VERSION ""

NS_ :

BS_:

BU_: TTC_580 TTC32

BO_ 2557673601 Axiomatic: 8 Vector__XXX
 SG_ Axiomatic_PWM : 0|32@1+ (1,0) [0|0] "" Vector__XXX

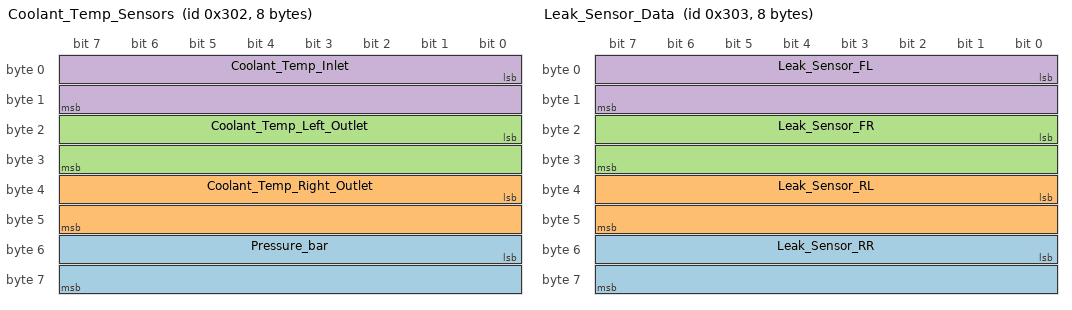
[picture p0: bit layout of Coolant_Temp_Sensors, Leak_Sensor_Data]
BO_ 770 Coolant_Temp_Sensors: 8 Vector__XXX
 SG_ Pressure_bar : 48|16@1+ (1,0) [0|65535] "bar" Vector__XXX
 SG_ Coolant_Temp_Right_Outlet : 32|16@1- (1,30.4) [-32737.6|32797.4] "C" Vector__XXX
 SG_ Coolant_Temp_Left_Outlet : 16|16@1- (1,30.4) [-32737.6|32797.4] "C" Vector__XXX
 SG_ Coolant_Temp_Inlet : 0|16@1- (1,30.4) [-32737.6|32797.4] "C" Vector__XXX

BO_ 771 Leak_Sensor_Data: 8 TTC32
 SG_ Leak_Sensor_RR : 48|16@1- (1,0) [-128|127] ""  TTC_580
 SG_ Leak_Sensor_RL : 32|16@1- (1,0) [-128|127] ""  TTC_580
 SG_ Leak_Sensor_FR : 16|16@1- (1,0) [-128|127] ""  TTC_580
 SG_ Leak_Sensor_FL : 0|16@1- (1,0) [-128|127] ""  TTC_580

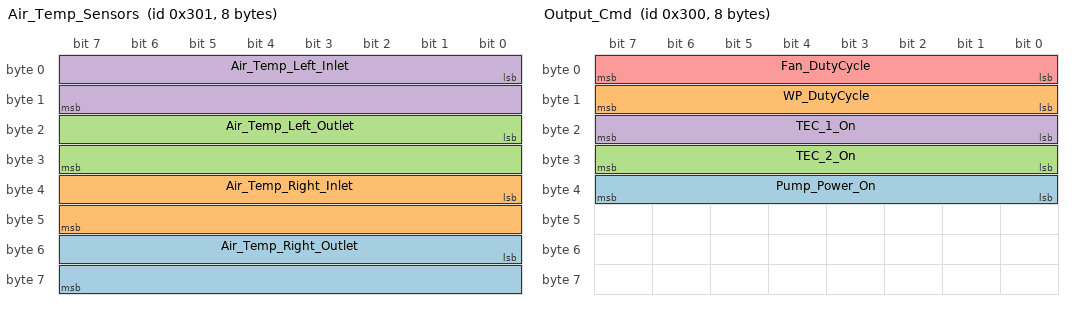
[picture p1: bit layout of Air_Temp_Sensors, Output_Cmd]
BO_ 769 Air_Temp_Sensors: 8 TTC32
 SG_ Air_Temp_Right_Outlet : 48|16@1- (1,0) [-32768|32767] "C"  TTC_580
 SG_ Air_Temp_Right_Inlet : 32|16@1- (1,0) [-32768|32767] "C"  TTC_580
 SG_ Air_Temp_Left_Outlet : 16|16@1- (1,0) [-32768|32767] "C"  TTC_580
 SG_ Air_Temp_Left_Inlet : 0|16@1- (1,0) [-32768|32767] "C"  TTC_580

BO_ 768 Output_Cmd: 8 TTC_580
 SG_ Pump_Power_On : 32|8@1+ (1,0) [0|255] ""  TTC32
 SG_ WP_DutyCycle : 8|8@1+ (1,0) [0|255] "%"  TTC32
 SG_ TEC_2_On : 24|8@1+ (1,0) [0|255] ""  TTC32
 SG_ TEC_1_On : 16|8@1+ (1,0) [0|255] ""  TTC32
 SG_ Fan_DutyCycle : 0|8@1+ (1,0) [0|255] "%"  TTC32

BA_DEF_  "BusType" STRING ;
BA_DEF_DEF_  "BusType" "CAN";
